# ZB32L030 register map
Vendor: ZBit.; Series: ZB32L03X; File version: 1.0
CPU: CM0+ r1p0, little endian, no MPU, no FPU, VTOR, 2 interrupt priority bits
Registers are 32-bit, read-write, reset 0x0 unless marked. A register's access mark holds for its fields unless they carry their own. Offsets are from the block's base; [hi:lo] are bit positions; {n}, {i} and the like mark numbered series.

## VC — Voltage Comparator
Base 0x40004080
Same registers: VC0 0x40004080
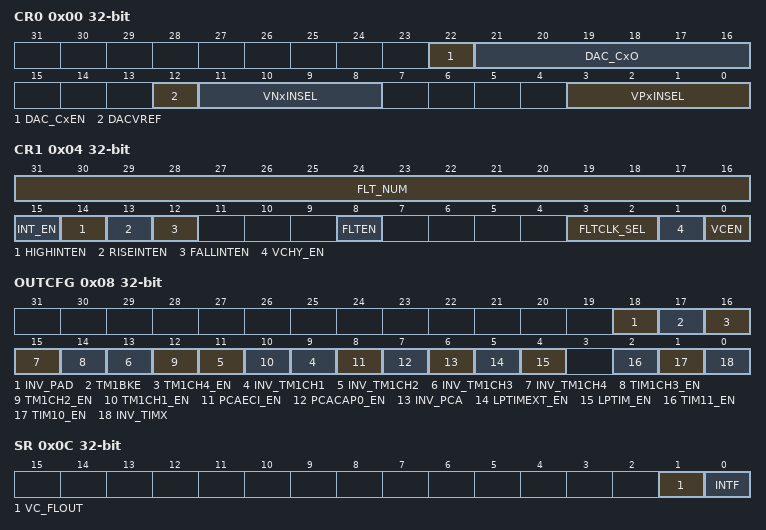
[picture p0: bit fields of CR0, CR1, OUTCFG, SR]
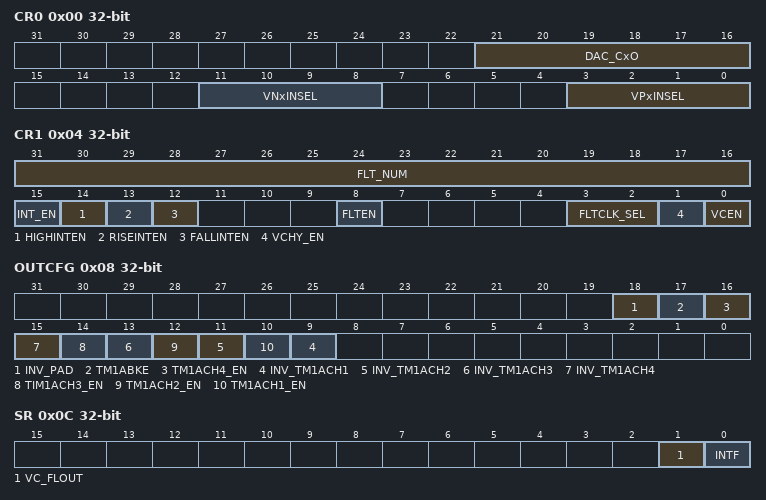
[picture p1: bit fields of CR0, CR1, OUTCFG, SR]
0x00 CR0 — VC Control 0
  [22] DAC_CxEN — DAC Cx (x=0,1) enable
  [21:16] DAC_CxO — DAC Voltage output
  [12] DACVREF
  [11:8] VNxINSEL — Input Voltage '-' select
    0=VC_N0 (VC_N0 input channel); 1=VC_N1 (VC_N0=1 input channel); {v}=VC_N{v} (VC_N{v} input channel) (v=2..7); 10=VC_N10 (VC_N10 input channel); 11=VC_N11 (VC_N11 (DAC0O) input channel); 13=VC_N13 (VC_N13 (1.2V) input channel); 14=VC_N14 (VC_N14 (ADCVREF) input channel); 15=VC_N15 (VC_N15 (VCAP) input channel)
  [3:0] VPxINSEL — Input Voltage '+' select
    {v}=VC_P{v} (VC_P{v} input channel) (v=4..15)
0x04 CR1 — VC Control 1
  [31:16] FLT_NUM — Sample counter
  [15] INT_EN — Interrupt enable
  [14] HIGHINTEN — High level interrupt enable
  [13] RISEINTEN — Rising interrupt enable
  [12] FALLINTEN — Falling interrupt enable
  [8] FLTEN — Digital Filter enable
  [3:2] FLTCLK_SEL — Filter clock select
  [1] VCHY_EN — VC Hysteresis Enable
  [0] VCEN — VC Enable
0x08 OUTCFG — VC Output Config
  [18] INV_PAD — INV PAD output
  [17] TM1BKE — TM1 brake
  [16] TM1CH4_EN — TM1CH4 enable
  [2n+7] INV_TM1CH{n} (n=1..4)
  [14] TIM1CH3_EN — TIM1CH3 enable
  [12] TM1CH2_EN — TM1CH2 enable
  [10] TM1CH1_EN — TM1CH1 enable
  [8] PCAECI_EN — PCAECI enable
  [7] PCACAP0_EN — PCACAP0 enable
  [6] INV_PCA
  [5] LPTIMEXT_EN — LPTIMEXT enable
  [4] LPTIM_EN — LPTIM enable
  [2] TIM11_EN — TIM11 enable
  [1] TIM10_EN — TIM10 enable
  [0] INV_TIMX
0x0C SR — VC Status Register
  [1] VC_FLOUT ro — VC filter output
  [0] INTF — VC interrupt

## VC1 — Voltage Comparator
Base 0x40004100
0x00 CR0 — VC Control 0
  [21:16] DAC_CxO — DAC Voltage output
  [11:8] VNxINSEL — Input Voltage '-' select
    {v}=VC_N{v} (VC_N{v} input channel) (v=4..10); 11=VC_N11 (VC_N11 (DAC1O) input channel); 14=VC_N14 (VC_N14 (1.2V) input channel); 15=VC_N15 (VC_N15 (VCAP) input channel)
  [3:0] VPxINSEL — Input Voltage '+' select
    {v}=VC_P{v} (VC_P{v} input channel) (v=0..15)
0x04 CR1 — VC Control 1
  [31:16] FLT_NUM — Sample counter
  [15] INT_EN — Interrupt enable
  [14] HIGHINTEN — High level interrupt enable
  [13] RISEINTEN — Rising interrupt enable
  [12] FALLINTEN — Falling interrupt enable
  [8] FLTEN — Digital Filter enable
  [3:2] FLTCLK_SEL — Filter clock select
  [1] VCHY_EN — VC Hysteresis Enable
  [0] VCEN — VC Enable
0x08 OUTCFG — VC Output Config
  [18] INV_PAD — INV PAD output
  [17] TM1ABKE — TM1A brake
  [16] TM1ACH4_EN — TM1ACH4 enable
  [2n+7] INV_TM1ACH{n} (n=1..4)
  [14] TIM1ACH3_EN — TIM1ACH3 enable
  [12] TM1ACH2_EN — TM1ACH2 enable
  [10] TM1ACH1_EN — TM1ACH1 enable
0x0C SR — VC0 Status Register
  [1] VC_FLOUT ro — VC filter output
  [0] INTF — VC interrupt

## DBG — Debug MCU
Base 0x40004C00
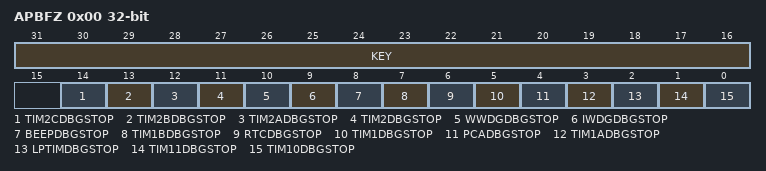
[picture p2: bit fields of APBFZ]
0x00 APBFZ — Mode Control Register
  [31:16] KEY wo — No comment
  [14] TIM2CDBGSTOP — No comment
  [13] TIM2BDBGSTOP — No comment
  [12] TIM2ADBGSTOP — No comment
  [11] TIM2DBGSTOP — No comment
  [10] WWDGDBGSTOP — No comment
  [9] IWDGDBGSTOP — No comment
  [8] BEEPDBGSTOP — No comment
  [7] TIM1BDBGSTOP — No comment
  [6] RTCDBGSTOP — No comment
  [5] TIM1DBGSTOP — No comment
  [4] PCADBGSTOP — No comment
  [3] TIM1ADBGSTOP — No comment
  [2] LPTIMDBGSTOP — No comment
  [1] TIM11DBGSTOP — No comment
  [0] TIM10DBGSTOP — No comment

## LVD
Base 0x40004000
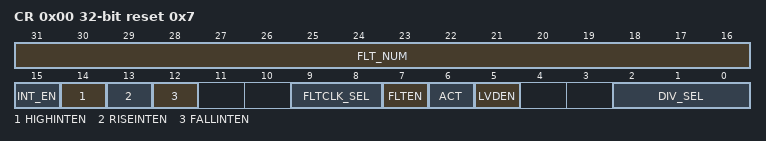
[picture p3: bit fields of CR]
0x00 CR reset 0x7 — Control Register
  [31:16] FLT_NUM — Sampling count
  [15] INT_EN — Interrupt enable
  [14] HIGHINTEN — High level trigger enable
  [13] RISEINTEN — Rising trigger enable
  [12] FALLINTEN — Falling trigger enable
  [9:8] FLTCLK_SEL — Filter clock selection
    0=NONE (disable); 1=PCLK (use PCLK); 2=SIRC (use SIRC)
  [7] FLTEN — Digital filter enable
  [6] ACT — No comment
  [5] LVDEN — LVD enable
  [2:0] DIV_SEL — Voltage division selection
    0=4_4 (4.4v); 1=4_0 (4.0v); 2=3_6 (3.6v); 3=3_3 (3.3v); 4=3_1 (3.1v); 5=2_9 (2.9v); 6=2_7 (2.7v); 7=2_5 (2.5v)
0x04 SR — LVD Status
  [0] INTF — Interrupt flag
